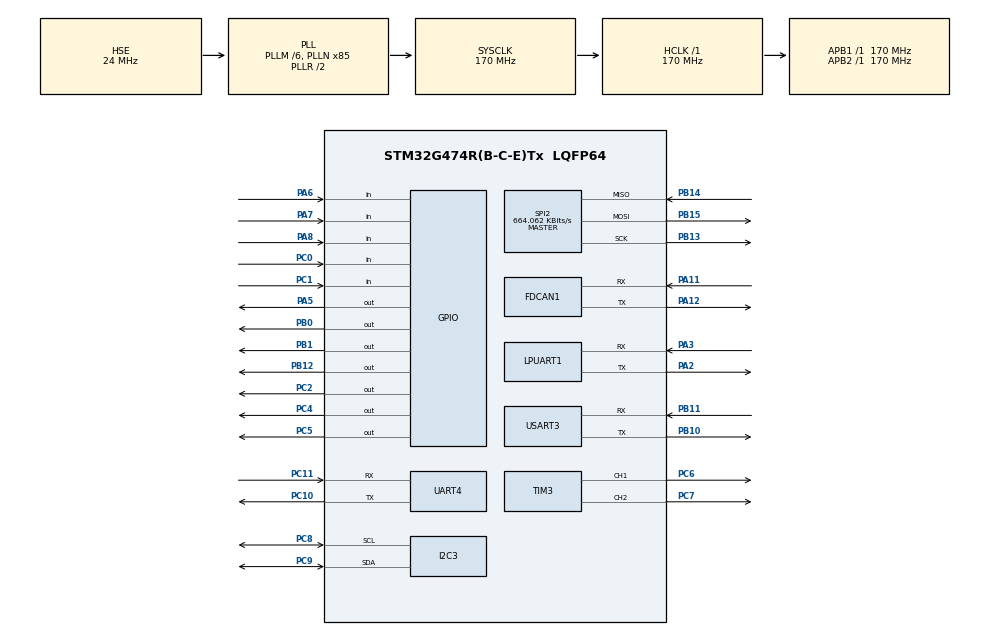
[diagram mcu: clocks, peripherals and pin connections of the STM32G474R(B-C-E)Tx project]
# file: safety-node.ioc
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Dma.Request0=TIM3_CH1
Dma.Request1=TIM3_CH2
Dma.TIM3_CH1.0.Direction=DMA_MEMORY_TO_PERIPH
Dma.TIM3_CH1.0.Instance=DMA1_Channel1
Dma.TIM3_CH1.0.MemDataAlignment=DMA_MDATAALIGN_HALFWORD
Dma.TIM3_CH1.0.MemInc=DMA_MINC_ENABLE
Dma.TIM3_CH1.0.Mode=DMA_NORMAL
Dma.TIM3_CH1.0.PeriphDataAlignment=DMA_PDATAALIGN_HALFWORD
Dma.TIM3_CH1.0.PeriphInc=DMA_PINC_DISABLE
Dma.TIM3_CH1.0.Priority=DMA_PRIORITY_HIGH
Dma.TIM3_CH2.1.Direction=DMA_MEMORY_TO_PERIPH
Dma.TIM3_CH2.1.Instance=DMA1_Channel2
Dma.TIM3_CH2.1.MemDataAlignment=DMA_MDATAALIGN_HALFWORD
Dma.TIM3_CH2.1.MemInc=DMA_MINC_ENABLE
Dma.TIM3_CH2.1.Mode=DMA_NORMAL
Dma.TIM3_CH2.1.PeriphDataAlignment=DMA_PDATAALIGN_HALFWORD
Dma.TIM3_CH2.1.PeriphInc=DMA_PINC_DISABLE
Dma.TIM3_CH2.1.Priority=DMA_PRIORITY_HIGH
FDCAN1.AutoRetransmission=ENABLE
FDCAN1.CalculateBaudRateNominal=499999
FDCAN1.CalculateTimeBitNominal=2000
FDCAN1.CalculateTimeQuantumNominal=117.64705882352942
FDCAN1.NominalPrescaler=20
FDCAN1.NominalSyncJumpWidth=2
FDCAN1.NominalTimeSeg1=14
FDCAN1.NominalTimeSeg2=2
FDCAN1.StdFiltersNbr=4
IWDG.Prescaler=IWDG_PRESCALER_32
IWDG.Reload=99
Mcu.Family=STM32G4
Mcu.Name=STM32G474R(B-C-E)Tx
Mcu.Package=LQFP64
NVIC.DMA1_Channel1_IRQn=true\:5\:0\:false\:false\:true\:false\:true\:true
NVIC.DMA1_Channel2_IRQn=true\:5\:0\:false\:false\:true\:false\:true\:true
NVIC.PriorityGroup=NVIC_PRIORITYGROUP_4
PA11.Mode=FDCAN_Activate
PA11.Signal=FDCAN1_RX
PA12.Mode=FDCAN_Activate
PA12.Signal=FDCAN1_TX
PA13.GPIO_Label=T_SWDIO
PA13.Signal=SYS_JTMS-SWDIO
PA14.GPIO_Label=T_SWCLK
PA14.Signal=SYS_JTCK-SWCLK
PA2.Mode=Asynchronous
PA2.Signal=LPUART1_TX
PA3.Mode=Asynchronous
PA3.Signal=LPUART1_RX
PA5.Signal=GPIO_Output
PA6.Signal=GPIO_Input
PA7.Signal=GPIO_Input
PA8.Signal=GPIO_Input
PB0.Signal=GPIO_Output
PB1.Signal=GPIO_Output
PB10.Mode=Asynchronous
PB10.Signal=USART3_TX
PB11.Mode=Asynchronous
PB11.Signal=USART3_RX
PB12.PinState=GPIO_PIN_SET
PB12.Signal=GPIO_Output
PB13.Mode=Full_Duplex_Master
PB13.Signal=SPI2_SCK
PB14.Mode=Full_Duplex_Master
PB14.Signal=SPI2_MISO
PB15.Mode=Full_Duplex_Master
PB15.Signal=SPI2_MOSI
PB3.GPIO_Label=T_SWO
PB3.Signal=SYS_JTDO-SWO
PC0.Signal=GPIO_Input
PC1.Signal=GPIO_Input
PC10.Mode=Asynchronous
PC10.Signal=UART4_TX
PC11.Mode=Asynchronous
PC11.Signal=UART4_RX
PC14-OSC32_IN.GPIO_Label=RCC_OSC32_IN
PC14-OSC32_IN.Mode=LSE-External-Oscillator
PC14-OSC32_IN.Signal=RCC_OSC32_IN
PC15-OSC32_OUT.GPIO_Label=RCC_OSC32_OUT
PC15-OSC32_OUT.Mode=LSE-External-Oscillator
PC15-OSC32_OUT.Signal=RCC_OSC32_OUT
PC2.Signal=GPIO_Output
PC4.Signal=GPIO_Output
PC5.Signal=GPIO_Output
PC6.Signal=S_TIM3_CH1
PC7.Signal=S_TIM3_CH2
PC8.Mode=I2C
PC8.Signal=I2C3_SCL
PC9.Mode=I2C
PC9.Signal=I2C3_SDA
PF0-OSC_IN.GPIO_Label=RCC_OSC_IN
PF0-OSC_IN.Mode=HSE-External-Oscillator
PF0-OSC_IN.Signal=RCC_OSC_IN
PF1-OSC_OUT.GPIO_Label=RCC_OSC_OUT
PF1-OSC_OUT.Mode=HSE-External-Oscillator
PF1-OSC_OUT.Signal=RCC_OSC_OUT
ProjectManager.HeapSize=0x200
ProjectManager.StackSize=0x400
ProjectManager.TargetToolchain=CMake
RCC.ADC12Freq_Value=170000000
RCC.ADC345Freq_Value=170000000
RCC.AHBFreq_Value=170000000
RCC.APB1Freq_Value=170000000
RCC.APB1TimFreq_Value=170000000
RCC.APB2Freq_Value=170000000
RCC.APB2TimFreq_Value=170000000
RCC.CortexFreq_Value=170000000
RCC.EXTERNAL_CLOCK_VALUE=12288000
RCC.HCLKFreq_Value=170000000
RCC.HSE_VALUE=24000000
RCC.HSI48_VALUE=48000000
RCC.HSI_VALUE=16000000
RCC.PLLM=RCC_PLLM_DIV6
RCC.PLLN=85
RCC.PLLSourceVirtual=RCC_PLLSOURCE_HSE
RCC.RTCClockSelection=RCC_RTCCLKSOURCE_LSE
RCC.SYSCLKFreq_VALUE=170000000
RCC.SYSCLKSource=RCC_SYSCLKSOURCE_PLLCLK
RCC.VCOOutputFreq_Value=340000000
SH.S_TIM3_CH1.0=TIM3_CH1,PWM Generation1 CH1
SH.S_TIM3_CH2.0=TIM3_CH2,PWM Generation2 CH2
SPI2.BaudRatePrescaler=SPI_BAUDRATEPRESCALER_256
SPI2.CLKPhase=SPI_PHASE_2EDGE
SPI2.CLKPolarity=SPI_POLARITY_HIGH
SPI2.CalculateBaudRate=664.062 KBits/s
SPI2.DataSize=SPI_DATASIZE_8BIT
SPI2.Direction=SPI_DIRECTION_2LINES
SPI2.Mode=SPI_MODE_MASTER
SPI2.VirtualType=VM_MASTER
TIM3.Channel-PWM\ Generation1\ CH1=TIM_CHANNEL_1
TIM3.Channel-PWM\ Generation2\ CH2=TIM_CHANNEL_2
USART3.VirtualMode-Asynchronous=VM_ASYNC
VP_IWDG_VS_IWDG.Mode=IWDG_Activate
VP_SYS_VS_DBSignals.Mode=DisableDeadBatterySignals
VP_TIM3_VS_ClockSourceINT.Mode=Internal
board=NUCLEO-G474RE

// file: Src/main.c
/* USER CODE BEGIN Header */
/**
  ******************************************************************************
  * @file           : main.c
  * @brief          : Main program body
  ******************************************************************************
  * @attention
  *
  * Copyright (c) 2026 STMicroelectronics.
  * All rights reserved.
  *
  * This software is licensed under terms that can be found in the LICENSE file
  * in the root directory of this software component.
  * If no LICENSE file comes with this software, it is provided AS-IS.
  *
  ******************************************************************************
  */
/* USER CODE END Header */
#include "main.h"

/* USER CODE BEGIN Includes */
#include "boot_checks.h"
/* USER CODE END Includes */

FDCAN_HandleTypeDef hfdcan1;

I2C_HandleTypeDef hi2c3;

IWDG_HandleTypeDef hiwdg;

UART_HandleTypeDef hlpuart1;
UART_HandleTypeDef huart4;
UART_HandleTypeDef huart3;

SPI_HandleTypeDef hspi2;

TIM_HandleTypeDef htim3;
DMA_HandleTypeDef hdma_tim3_ch1;
DMA_HandleTypeDef hdma_tim3_ch2;

void SystemClock_Config(void);
static void MX_GPIO_Init(void);
static void MX_DMA_Init(void);
static void MX_FDCAN1_Init(void);
static void MX_I2C3_Init(void);
static void MX_LPUART1_UART_Init(void);
static void MX_UART4_Init(void);
static void MX_USART3_UART_Init(void);
static void MX_SPI2_Init(void);
static void MX_TIM3_Init(void);
static void MX_IWDG_Init(void);

int main(void)
{

  /* USER CODE BEGIN 1 */
  /* First thing in main: read and clear RCC->CSR (before HAL/clock init), count abnormal resets. */
  boot_reset_cause_capture();
  /* USER CODE END 1 */

  /* MCU Configuration--------------------------------------------------------*/

  /* Reset of all peripherals, Initializes the Flash interface and the Systick. */
  HAL_Init();

  /* Configure the system clock */
  SystemClock_Config();

  /* Initialize all configured peripherals */
  MX_GPIO_Init();
  MX_DMA_Init();
  MX_FDCAN1_Init();
  MX_I2C3_Init();
  MX_LPUART1_UART_Init();
  MX_UART4_Init();
  MX_USART3_UART_Init();
  MX_SPI2_Init();
  MX_TIM3_Init();
  MX_IWDG_Init();
  /* USER CODE BEGIN 2 */
  /* Option bytes / IWDG / BOR against cubemx/README.md: recorded only, never a halt (T77). */
  boot_hw_config_check();
#if defined(SAFETY_BOOT_START_FDCAN)
  /* TODO(T13): the FDCAN port starts the controller here. Off in this image (no frame is
   * exchanged, and Renode's M_CAN model does not store NBTP, so the read-back would fail).
   * boot_fdcan_start() checks the run-time kernel clock and the NBTP read-back with
   * can_timing_nbtp_ok(); on a mismatch it leaves the controller stopped and sets
   * boot_can_fault() (no reset: the rt-core inputs stay invalid and the D-042 own-IMU
   * fallback and the blind spot keep running). */
  (void)boot_fdcan_start(&hfdcan1, BOOT_FDCAN1_EXPECTED_BPS);
#endif
  /* USER CODE END 2 */

  /* Infinite loop */
  while (1)
  {

    /* USER CODE BEGIN 3 */
    /* One IWDG refresh per super-loop iteration (about 100 ms timeout). Placeholder:
     * the watchdog/heartbeat module owns this call from T13, after the decision steps. */
    if (HAL_IWDG_Refresh(&hiwdg) != HAL_OK)
    {
      Error_Handler();
    }
  }
  /* USER CODE END 3 */
}

void SystemClock_Config(void)
{
  RCC_OscInitTypeDef RCC_OscInitStruct = {0};
  RCC_ClkInitTypeDef RCC_ClkInitStruct = {0};

  /** Configure the main internal regulator output voltage
  */
  HAL_PWREx_ControlVoltageScaling(PWR_REGULATOR_VOLTAGE_SCALE1_BOOST);

  /** Initializes the RCC Oscillators according to the specified parameters
  * in the RCC_OscInitTypeDef structure.
  */
  RCC_OscInitStruct.OscillatorType = RCC_OSCILLATORTYPE_LSI|RCC_OSCILLATORTYPE_HSE;
  RCC_OscInitStruct.HSEState = RCC_HSE_ON;
  RCC_OscInitStruct.LSIState = RCC_LSI_ON;
  RCC_OscInitStruct.PLL.PLLState = RCC_PLL_ON;
  RCC_OscInitStruct.PLL.PLLSource = RCC_PLLSOURCE_HSE;
  RCC_OscInitStruct.PLL.PLLM = RCC_PLLM_DIV6;
  RCC_OscInitStruct.PLL.PLLN = 85;
  RCC_OscInitStruct.PLL.PLLP = RCC_PLLP_DIV2;
  RCC_OscInitStruct.PLL.PLLQ = RCC_PLLQ_DIV2;
  RCC_OscInitStruct.PLL.PLLR = RCC_PLLR_DIV2;
  if (HAL_RCC_OscConfig(&RCC_OscInitStruct) != HAL_OK)
  {
    Error_Handler();
  }

  /** Initializes the CPU, AHB and APB buses clocks
  */
  RCC_ClkInitStruct.ClockType = RCC_CLOCKTYPE_HCLK|RCC_CLOCKTYPE_SYSCLK
                              |RCC_CLOCKTYPE_PCLK1|RCC_CLOCKTYPE_PCLK2;
  RCC_ClkInitStruct.SYSCLKSource = RCC_SYSCLKSOURCE_PLLCLK;
  RCC_ClkInitStruct.AHBCLKDivider = RCC_SYSCLK_DIV1;
  RCC_ClkInitStruct.APB1CLKDivider = RCC_HCLK_DIV1;
  RCC_ClkInitStruct.APB2CLKDivider = RCC_HCLK_DIV1;

  if (HAL_RCC_ClockConfig(&RCC_ClkInitStruct, FLASH_LATENCY_4) != HAL_OK)
  {
    Error_Handler();
  }
}

static void MX_FDCAN1_Init(void)
{

  hfdcan1.Instance = FDCAN1;
  hfdcan1.Init.ClockDivider = FDCAN_CLOCK_DIV1;
  hfdcan1.Init.FrameFormat = FDCAN_FRAME_CLASSIC;
  hfdcan1.Init.Mode = FDCAN_MODE_NORMAL;
  hfdcan1.Init.AutoRetransmission = ENABLE;
  hfdcan1.Init.TransmitPause = DISABLE;
  hfdcan1.Init.ProtocolException = DISABLE;
  hfdcan1.Init.NominalPrescaler = 20;
  hfdcan1.Init.NominalSyncJumpWidth = 2;
  hfdcan1.Init.NominalTimeSeg1 = 14;
  hfdcan1.Init.NominalTimeSeg2 = 2;
  hfdcan1.Init.DataPrescaler = 1;
  hfdcan1.Init.DataSyncJumpWidth = 1;
  hfdcan1.Init.DataTimeSeg1 = 1;
  hfdcan1.Init.DataTimeSeg2 = 1;
  hfdcan1.Init.StdFiltersNbr = 4;
  hfdcan1.Init.ExtFiltersNbr = 0;
  hfdcan1.Init.TxFifoQueueMode = FDCAN_TX_FIFO_OPERATION;
  if (HAL_FDCAN_Init(&hfdcan1) != HAL_OK)
  {
    Error_Handler();
  }

}

static void MX_I2C3_Init(void)
{

  hi2c3.Instance = I2C3;
  hi2c3.Init.Timing = 0x00303D5B;
  hi2c3.Init.OwnAddress1 = 0;
  hi2c3.Init.AddressingMode = I2C_ADDRESSINGMODE_7BIT;
  hi2c3.Init.DualAddressMode = I2C_DUALADDRESS_DISABLE;
  hi2c3.Init.OwnAddress2 = 0;
  hi2c3.Init.OwnAddress2Masks = I2C_OA2_NOMASK;
  hi2c3.Init.GeneralCallMode = I2C_GENERALCALL_DISABLE;
  hi2c3.Init.NoStretchMode = I2C_NOSTRETCH_DISABLE;
  if (HAL_I2C_Init(&hi2c3) != HAL_OK)
  {
    Error_Handler();
  }

  /** Configure Analogue filter
  */
  if (HAL_I2CEx_ConfigAnalogFilter(&hi2c3, I2C_ANALOGFILTER_ENABLE) != HAL_OK)
  {
    Error_Handler();
  }

  /** Configure Digital filter
  */
  if (HAL_I2CEx_ConfigDigitalFilter(&hi2c3, 0) != HAL_OK)
  {
    Error_Handler();
  }

}

static void MX_IWDG_Init(void)
{

  hiwdg.Instance = IWDG;
  hiwdg.Init.Prescaler = IWDG_PRESCALER_32;
  hiwdg.Init.Window = 4095;
  hiwdg.Init.Reload = 99;
  if (HAL_IWDG_Init(&hiwdg) != HAL_OK)
  {
    Error_Handler();
  }

}

static void MX_LPUART1_UART_Init(void)
{

  hlpuart1.Instance = LPUART1;
  hlpuart1.Init.BaudRate = 209700;
  hlpuart1.Init.WordLength = UART_WORDLENGTH_8B;
  hlpuart1.Init.StopBits = UART_STOPBITS_1;
  hlpuart1.Init.Parity = UART_PARITY_NONE;
  hlpuart1.Init.Mode = UART_MODE_TX_RX;
  hlpuart1.Init.HwFlowCtl = UART_HWCONTROL_NONE;
  hlpuart1.Init.OneBitSampling = UART_ONE_BIT_SAMPLE_DISABLE;
  hlpuart1.Init.ClockPrescaler = UART_PRESCALER_DIV1;
  hlpuart1.AdvancedInit.AdvFeatureInit = UART_ADVFEATURE_NO_INIT;
  if (HAL_UART_Init(&hlpuart1) != HAL_OK)
  {
    Error_Handler();
  }
  if (HAL_UARTEx_SetTxFifoThreshold(&hlpuart1, UART_TXFIFO_THRESHOLD_1_8) != HAL_OK)
  {
    Error_Handler();
  }
  if (HAL_UARTEx_SetRxFifoThreshold(&hlpuart1, UART_RXFIFO_THRESHOLD_1_8) != HAL_OK)
  {
    Error_Handler();
  }
  if (HAL_UARTEx_DisableFifoMode(&hlpuart1) != HAL_OK)
  {
    Error_Handler();
  }

}

static void MX_UART4_Init(void)
{

  huart4.Instance = UART4;
  huart4.Init.BaudRate = 115200;
  huart4.Init.WordLength = UART_WORDLENGTH_8B;
  huart4.Init.StopBits = UART_STOPBITS_1;
  huart4.Init.Parity = UART_PARITY_NONE;
  huart4.Init.Mode = UART_MODE_TX_RX;
  huart4.Init.HwFlowCtl = UART_HWCONTROL_NONE;
  huart4.Init.OverSampling = UART_OVERSAMPLING_16;
  huart4.Init.OneBitSampling = UART_ONE_BIT_SAMPLE_DISABLE;
  huart4.Init.ClockPrescaler = UART_PRESCALER_DIV1;
  huart4.AdvancedInit.AdvFeatureInit = UART_ADVFEATURE_NO_INIT;
  if (HAL_UART_Init(&huart4) != HAL_OK)
  {
    Error_Handler();
  }
  if (HAL_UARTEx_SetTxFifoThreshold(&huart4, UART_TXFIFO_THRESHOLD_1_8) != HAL_OK)
  {
    Error_Handler();
  }
  if (HAL_UARTEx_SetRxFifoThreshold(&huart4, UART_RXFIFO_THRESHOLD_1_8) != HAL_OK)
  {
    Error_Handler();
  }
  if (HAL_UARTEx_DisableFifoMode(&huart4) != HAL_OK)
  {
    Error_Handler();
  }

}

static void MX_USART3_UART_Init(void)
{

  huart3.Instance = USART3;
  huart3.Init.BaudRate = 115200;
  huart3.Init.WordLength = UART_WORDLENGTH_8B;
  huart3.Init.StopBits = UART_STOPBITS_1;
  huart3.Init.Parity = UART_PARITY_NONE;
  huart3.Init.Mode = UART_MODE_TX_RX;
  huart3.Init.HwFlowCtl = UART_HWCONTROL_NONE;
  huart3.Init.OverSampling = UART_OVERSAMPLING_16;
  huart3.Init.OneBitSampling = UART_ONE_BIT_SAMPLE_DISABLE;
  huart3.Init.ClockPrescaler = UART_PRESCALER_DIV1;
  huart3.AdvancedInit.AdvFeatureInit = UART_ADVFEATURE_NO_INIT;
  if (HAL_UART_Init(&huart3) != HAL_OK)
  {
    Error_Handler();
  }
  if (HAL_UARTEx_SetTxFifoThreshold(&huart3, UART_TXFIFO_THRESHOLD_1_8) != HAL_OK)
  {
    Error_Handler();
  }
  if (HAL_UARTEx_SetRxFifoThreshold(&huart3, UART_RXFIFO_THRESHOLD_1_8) != HAL_OK)
  {
    Error_Handler();
  }
  if (HAL_UARTEx_DisableFifoMode(&huart3) != HAL_OK)
  {
    Error_Handler();
  }

}

static void MX_SPI2_Init(void)
{

  /* SPI2 parameter configuration*/
  hspi2.Instance = SPI2;
  hspi2.Init.Mode = SPI_MODE_MASTER;
  hspi2.Init.Direction = SPI_DIRECTION_2LINES;
  hspi2.Init.DataSize = SPI_DATASIZE_8BIT;
  hspi2.Init.CLKPolarity = SPI_POLARITY_HIGH;
  hspi2.Init.CLKPhase = SPI_PHASE_2EDGE;
  hspi2.Init.NSS = SPI_NSS_SOFT;
  hspi2.Init.BaudRatePrescaler = SPI_BAUDRATEPRESCALER_256;
  hspi2.Init.FirstBit = SPI_FIRSTBIT_MSB;
  hspi2.Init.TIMode = SPI_TIMODE_DISABLE;
  hspi2.Init.CRCCalculation = SPI_CRCCALCULATION_DISABLE;
  hspi2.Init.CRCPolynomial = 7;
  hspi2.Init.CRCLength = SPI_CRC_LENGTH_DATASIZE;
  hspi2.Init.NSSPMode = SPI_NSS_PULSE_DISABLE;
  if (HAL_SPI_Init(&hspi2) != HAL_OK)
  {
    Error_Handler();
  }

}

static void MX_TIM3_Init(void)
{

  TIM_ClockConfigTypeDef sClockSourceConfig = {0};
  TIM_MasterConfigTypeDef sMasterConfig = {0};
  TIM_OC_InitTypeDef sConfigOC = {0};

  htim3.Instance = TIM3;
  htim3.Init.Prescaler = 0;
  htim3.Init.CounterMode = TIM_COUNTERMODE_UP;
  htim3.Init.Period = 65535;
  htim3.Init.ClockDivision = TIM_CLOCKDIVISION_DIV1;
  htim3.Init.AutoReloadPreload = TIM_AUTORELOAD_PRELOAD_DISABLE;
  if (HAL_TIM_Base_Init(&htim3) != HAL_OK)
  {
    Error_Handler();
  }
  sClockSourceConfig.ClockSource = TIM_CLOCKSOURCE_INTERNAL;
  if (HAL_TIM_ConfigClockSource(&htim3, &sClockSourceConfig) != HAL_OK)
  {
    Error_Handler();
  }
  if (HAL_TIM_PWM_Init(&htim3) != HAL_OK)
  {
    Error_Handler();
  }
  sMasterConfig.MasterOutputTrigger = TIM_TRGO_RESET;
  sMasterConfig.MasterSlaveMode = TIM_MASTERSLAVEMODE_DISABLE;
  if (HAL_TIMEx_MasterConfigSynchronization(&htim3, &sMasterConfig) != HAL_OK)
  {
    Error_Handler();
  }
  sConfigOC.OCMode = TIM_OCMODE_PWM1;
  sConfigOC.Pulse = 0;
  sConfigOC.OCPolarity = TIM_OCPOLARITY_HIGH;
  sConfigOC.OCFastMode = TIM_OCFAST_DISABLE;
  if (HAL_TIM_PWM_ConfigChannel(&htim3, &sConfigOC, TIM_CHANNEL_1) != HAL_OK)
  {
    Error_Handler();
  }
  if (HAL_TIM_PWM_ConfigChannel(&htim3, &sConfigOC, TIM_CHANNEL_2) != HAL_OK)
  {
    Error_Handler();
  }
  HAL_TIM_MspPostInit(&htim3);

}

static void MX_DMA_Init(void)
{

  /* DMA controller clock enable */
  __HAL_RCC_DMAMUX1_CLK_ENABLE();
  __HAL_RCC_DMA1_CLK_ENABLE();

  /* DMA interrupt init */
  /* DMA1_Channel1_IRQn interrupt configuration */
  HAL_NVIC_SetPriority(DMA1_Channel1_IRQn, 5, 0);
  HAL_NVIC_EnableIRQ(DMA1_Channel1_IRQn);
  /* DMA1_Channel2_IRQn interrupt configuration */
  HAL_NVIC_SetPriority(DMA1_Channel2_IRQn, 5, 0);
  HAL_NVIC_EnableIRQ(DMA1_Channel2_IRQn);

}

static void MX_GPIO_Init(void)
{
  GPIO_InitTypeDef GPIO_InitStruct = {0};

  /* GPIO Ports Clock Enable */
  __HAL_RCC_GPIOC_CLK_ENABLE();
  __HAL_RCC_GPIOF_CLK_ENABLE();
  __HAL_RCC_GPIOA_CLK_ENABLE();
  __HAL_RCC_GPIOB_CLK_ENABLE();

  /*Configure GPIO pin Output Level */
  HAL_GPIO_WritePin(GPIOC, GPIO_PIN_2|GPIO_PIN_4|GPIO_PIN_5, GPIO_PIN_RESET);

  /*Configure GPIO pin Output Level */
  HAL_GPIO_WritePin(GPIOA, GPIO_PIN_5, GPIO_PIN_RESET);

  /*Configure GPIO pin Output Level */
  HAL_GPIO_WritePin(GPIOB, GPIO_PIN_0|GPIO_PIN_1, GPIO_PIN_RESET);

  /*Configure GPIO pin Output Level */
  HAL_GPIO_WritePin(GPIOB, GPIO_PIN_12, GPIO_PIN_SET);

  /*Configure GPIO pins : PC0 PC1 */
  GPIO_InitStruct.Pin = GPIO_PIN_0|GPIO_PIN_1;
  GPIO_InitStruct.Mode = GPIO_MODE_INPUT;
  GPIO_InitStruct.Pull = GPIO_NOPULL;
  HAL_GPIO_Init(GPIOC, &GPIO_InitStruct);

  /*Configure GPIO pins : PC2 PC4 PC5 */
  GPIO_InitStruct.Pin = GPIO_PIN_2|GPIO_PIN_4|GPIO_PIN_5;
  GPIO_InitStruct.Mode = GPIO_MODE_OUTPUT_PP;
  GPIO_InitStruct.Pull = GPIO_NOPULL;
  GPIO_InitStruct.Speed = GPIO_SPEED_FREQ_LOW;
  HAL_GPIO_Init(GPIOC, &GPIO_InitStruct);

  /*Configure GPIO pin : PA5 */
  GPIO_InitStruct.Pin = GPIO_PIN_5;
  GPIO_InitStruct.Mode = GPIO_MODE_OUTPUT_PP;
  GPIO_InitStruct.Pull = GPIO_NOPULL;
  GPIO_InitStruct.Speed = GPIO_SPEED_FREQ_LOW;
  HAL_GPIO_Init(GPIOA, &GPIO_InitStruct);

  /*Configure GPIO pins : PA6 PA7 PA8 */
  GPIO_InitStruct.Pin = GPIO_PIN_6|GPIO_PIN_7|GPIO_PIN_8;
  GPIO_InitStruct.Mode = GPIO_MODE_INPUT;
  GPIO_InitStruct.Pull = GPIO_NOPULL;
  HAL_GPIO_Init(GPIOA, &GPIO_InitStruct);

  /*Configure GPIO pins : PB0 PB1 PB12 */
  GPIO_InitStruct.Pin = GPIO_PIN_0|GPIO_PIN_1|GPIO_PIN_12;
  GPIO_InitStruct.Mode = GPIO_MODE_OUTPUT_PP;
  GPIO_InitStruct.Pull = GPIO_NOPULL;
  GPIO_InitStruct.Speed = GPIO_SPEED_FREQ_LOW;
  HAL_GPIO_Init(GPIOB, &GPIO_InitStruct);

}

/* USER CODE BEGIN 4 */
/**
  * @brief Drive every actuator output low (de-energise the immobilizer relay coils, the
  *        dead-man kick and the mirror LEDs). Callable from Error_Handler and from the fault
  *        handlers: direct register writes, no HAL call, no dependency on MX_GPIO_Init (the
  *        GPIO clocks are enabled here, the pins are driven low through the atomic BSRR reset
  *        half). Set: PC2 DEADMAN_KICK, PC4 IMMO_SET, PC5 IMMO_RESET (GPIOC), PB0 / PB1
  *        mirror LEDs left / right (GPIOB), PA5 status LED LD2 (GPIOA, not safety relevant).
  *        A coil left energised during a fault could complete an unintended latch.
  */
void safety_outputs_off(void)
{
  boot_outputs_off(); /* always_inline register writes (User/boot_checks.h) */
}

/* USER CODE END 4 */

void Error_Handler(void)
{
  /* USER CODE BEGIN Error_Handler_Debug */
  /* User can add his own implementation to report the HAL error return state */
  /* Outputs off and reset (always_inline, stack-free, never returns: User/boot_checks.h). No infinite spin; the IWDG stays armed as the backstop should the
   * reset request itself fail. NOT "back to unlocked": the latching immobilizer relay keeps
   * a LOCKED latch through a reset, and a truncated SET pulse can leave it in an unknown
   * state (D-097). Boot state handling is T13: treat the state as unknown and start the
   * 10 s unlock timer; a boot never pulses the relay (repo CLAUDE.md rule 5). */
  boot_safe_state(FAULT_TAG_ERROR_HANDLER);
  /* USER CODE END Error_Handler_Debug */
}
